AUTOSAR XML (schema 4-1-3)
standard types defined: uint16, uint32, uint8
package /UAES/ASW/DataConstrs
  range DC_uint16: raw 0..65535
  range DC_uint32: raw 0..4294967295
  range DC_uint8: raw 0..255
package /UAES/ASW/DataTypeMappingSets
  data type mapping set EFuse_DD
package /UAES/ASW/ImplementationDataTypes
  impl type rt_Array_uint8_9: category=ARRAY, sw-calibration-access=READ-ONLY, type-emitter=RTE
    element rt_Array_uint8_9: array-size=9, array-size-semantics=FIXED-SIZE, implementation-data-type=uint8
package /UAES/ASW/PortInterfaces
  client server interface EFuse_DrvMode_Set
    operation EFuse_DrvMode_Set: possible-error=E_NOT_OK
      arg EFuse_ID: type=uint16, direction=IN, server-argument-impl-policy=USE-ARGUMENT-TYPE
      arg DrvMode: type=uint8, direction=IN, server-argument-impl-policy=USE-ARGUMENT-TYPE
    error E_NOT_OK: error-code=1
  sender receiver interface EFuse_ActUseFuseChInfo: invalidation-policy{data-element=EFuse_ActUseFuseChInfo/Val, handle-invalid=DONT-INVALIDATE}
    data Val: sw-calibration-access=READ-ONLY, type=uint32
  sender receiver interface EFuse_au8stFuse: invalidation-policy{data-element=EFuse_au8stFuse/Val, handle-invalid=DONT-INVALIDATE}
    data Val: sw-calibration-access=READ-ONLY, type=rt_Array_uint8_9
package /UAES/ASW/SwComponentTypes
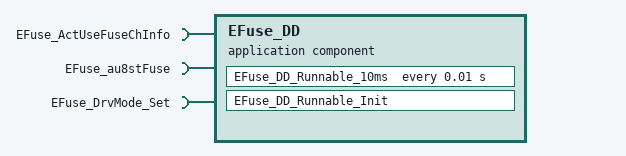
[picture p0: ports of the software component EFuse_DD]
  application sw component type EFuse_DD
    require port EFuse_ActUseFuseChInfo: nonqueued-receiver-com-spec{data-element=EFuse_ActUseFuseChInfo/Val, filter=data-filter-type=ALWAYS, init-value=0}, required-interface=EFuse_ActUseFuseChInfo
    require port EFuse_au8stFuse: nonqueued-receiver-com-spec{data-element=EFuse_au8stFuse/Val, filter=data-filter-type=ALWAYS, init-value=9 x 0}, required-interface=EFuse_au8stFuse
    require port EFuse_DrvMode_Set: client-com-spec=EFuse_DrvMode_Set, required-interface=EFuse_DrvMode_Set
    behavior EFuse_DD_InternalBehavior: data-type-mapping=EFuse_DD
      timing event TMT_EFuse_DD_Runnable_10ms: start-on-event=EFuse_DD_Runnable_10ms, period=0.01
      init event EFuse_DD_Runnable_InitEvent: start-on-event=EFuse_DD_Runnable_Init
      runnable EFuse_DD_Runnable_10ms
        data-read-access:
          access READ_EFuse_ActUseFuseChInfo_Val: accessed-variable=EFuse_ActUseFuseChInfo.Val
          access READ_EFuse_au8stFuse_Val: accessed-variable=EFuse_au8stFuse.Val
        sync call SC_EFuse_DrvMode_Set_EFuse_DrvMode_Set: operation=EFuse_DrvMode_Set.EFuse_DrvMode_Set, timeout=0
      runnable EFuse_DD_Runnable_Init
  swc implementation EFuse_DD_Implementation: behavior=EFuse_DD_InternalBehavior
    code-descriptors:
      code Default: artifact-descriptors=autosar-engineering-object={short-label=Default, category=SWSRC}
